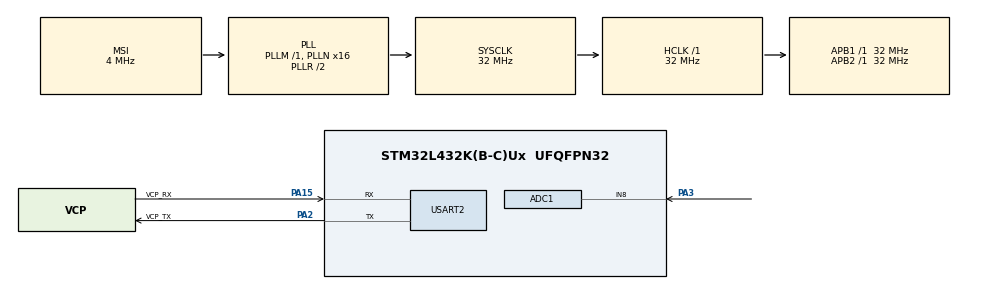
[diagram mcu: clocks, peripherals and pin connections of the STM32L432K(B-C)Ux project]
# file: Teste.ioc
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ADC1.Channel-0\#ChannelRegularConversion=ADC_CHANNEL_8
ADC1.ClockPrescaler=ADC_CLOCK_ASYNC_DIV1
ADC1.EnableInjectedConversion=DISABLE
ADC1.NbrOfConversionFlag=1
ADC1.OffsetNumber-0\#ChannelRegularConversion=ADC_OFFSET_NONE
ADC1.Overrun=ADC_OVR_DATA_PRESERVED
ADC1.Rank-0\#ChannelRegularConversion=1
ADC1.SamplingTime-0\#ChannelRegularConversion=ADC_SAMPLETIME_2CYCLES_5
ADC1.master=1
Mcu.Family=STM32L4
Mcu.Name=STM32L432K(B-C)Ux
Mcu.Package=UFQFPN32
NVIC.ADC1_IRQn=true\:0\:0\:false\:false\:true\:true\:true
NVIC.PriorityGroup=NVIC_PRIORITYGROUP_4
NVIC.TIM1_UP_TIM16_IRQn=true\:0\:0\:false\:false\:true\:true\:true
PA0.GPIO_Label=MCO [High speed clock in]
PA0.Mode=HSE-External-Clock-Source-for-LittleOrca
PA0.Signal=RCC_CK_IN
PA13\ (JTMS-SWDIO).GPIO_Label=SWDIO
PA13\ (JTMS-SWDIO).Mode=Trace_Asynchronous_SW
PA13\ (JTMS-SWDIO).Signal=SYS_JTMS-SWDIO
PA14\ (JTCK-SWCLK).GPIO_Label=SWCLK
PA14\ (JTCK-SWCLK).Mode=Trace_Asynchronous_SW
PA14\ (JTCK-SWCLK).Signal=SYS_JTCK-SWCLK
PA15\ (JTDI).GPIO_Label=VCP_RX
PA15\ (JTDI).Mode=Asynchronous
PA15\ (JTDI).Signal=USART2_RX
PA2.GPIO_Label=VCP_TX
PA2.Mode=Asynchronous
PA2.Signal=USART2_TX
PA3.Signal=ADCx_IN8
PB3\ (JTDO-TRACESWO).Mode=Trace_Asynchronous_SW
PB3\ (JTDO-TRACESWO).Signal=SYS_JTDO-SWO
PC14-OSC32_IN\ (PC14).Mode=LSE-External-Oscillator
PC14-OSC32_IN\ (PC14).Signal=RCC_OSC32_IN
PC15-OSC32_OUT\ (PC15).Mode=LSE-External-Oscillator
PC15-OSC32_OUT\ (PC15).Signal=RCC_OSC32_OUT
ProjectManager.HeapSize=0x200
ProjectManager.StackSize=0x400
ProjectManager.TargetToolchain=STM32CubeIDE
RCC.ADCFreq_Value=8000000
RCC.AHBFreq_Value=32000000
RCC.APB1Freq_Value=32000000
RCC.APB1TimFreq_Value=32000000
RCC.APB2Freq_Value=32000000
RCC.APB2TimFreq_Value=32000000
RCC.CortexFreq_Value=32000000
RCC.HCLKFreq_Value=32000000
RCC.HSE_VALUE=8000000
RCC.HSI16_VALUE=16000000
RCC.HSI48_VALUE=48000000
RCC.HSI_VALUE=16000000
RCC.MSI_VALUE=4000000
RCC.PLLMUL=RCC_PLLMUL_4
RCC.PLLN=16
RCC.PLLSAI1N=16
RCC.PLLSAI1R=RCC_PLLR_DIV8
RCC.SYSCLKFreq_VALUE=32000000
RCC.SYSCLKSource=RCC_SYSCLKSOURCE_PLLCLK
RCC.USBFreq_Value=32000000
RCC.VCOOutputFreq_Value=64000000
SH.ADCx_IN8.0=ADC1_IN8,IN8-Single-Ended
TIM16.Period=8000
USART2.VirtualMode-Asynchronous=VM_ASYNC
VP_TIM16_VS_ClockSourceINT.Mode=Enable_Timer
board=NUCLEO-L432KC

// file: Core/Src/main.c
/* USER CODE BEGIN Header */
/**
  ******************************************************************************
  * @file           : main.c
  * @brief          : Main program body
  ******************************************************************************
  * @attention
  *
  * <h2><center>&copy; Copyright (c) 2021 STMicroelectronics.
  * All rights reserved.</center></h2>
  *
  * This software component is licensed by ST under BSD 3-Clause license,
  * the "License"; You may not use this file except in compliance with the
  * License. You may obtain a copy of the License at:
  *                        opensource.org/licenses/BSD-3-Clause
  *
  ******************************************************************************
  */
/* USER CODE END Header */
#include "main.h"

ADC_HandleTypeDef hadc1;

TIM_HandleTypeDef htim16;

UART_HandleTypeDef huart2;

/* USER CODE BEGIN PV */
volatile uint32_t amostra;

/* USER CODE END PV */

void SystemClock_Config(void);
static void MX_GPIO_Init(void);
static void MX_USART2_UART_Init(void);
static void MX_ADC1_Init(void);
static void MX_TIM16_Init(void);

/* USER CODE BEGIN 0 */
void HAL_TIM_PeriodElapsedCallback(TIM_HandleTypeDef *htim)
{
	if( htim->Instance == htim16.Instance )
	{
		HAL_ADCEx_Calibration_Start(&hadc1, ADC_SINGLE_ENDED);
		HAL_ADC_Start(&hadc1);
		if( HAL_ADC_PollForConversion(&hadc1, 1) == HAL_TIMEOUT )
		{
		 // Sinalizar falha de timeout.
		}
		amostra = HAL_ADC_GetValue(&hadc1);
	}
}
/* USER CODE END 0 */

int main(void)
{

  /* MCU Configuration--------------------------------------------------------*/

  /* Reset of all peripherals, Initializes the Flash interface and the Systick. */
  HAL_Init();

  /* Configure the system clock */
  SystemClock_Config();

  /* Initialize all configured peripherals */
  MX_GPIO_Init();
  MX_USART2_UART_Init();
  MX_ADC1_Init();
  MX_TIM16_Init();
  /* USER CODE BEGIN 2 */
  HAL_TIM_Base_Start_IT(&htim16);
  /* USER CODE END 2 */

  /* Infinite loop */
  while (1)
  {

  }
}

void SystemClock_Config(void)
{
  RCC_OscInitTypeDef RCC_OscInitStruct = {0};
  RCC_ClkInitTypeDef RCC_ClkInitStruct = {0};

  /** Configure the main internal regulator output voltage
  */
  if (HAL_PWREx_ControlVoltageScaling(PWR_REGULATOR_VOLTAGE_SCALE1) != HAL_OK)
  {
    Error_Handler();
  }
  /** Configure LSE Drive Capability
  */
  HAL_PWR_EnableBkUpAccess();
  __HAL_RCC_LSEDRIVE_CONFIG(RCC_LSEDRIVE_LOW);
  /** Initializes the RCC Oscillators according to the specified parameters
  * in the RCC_OscInitTypeDef structure.
  */
  RCC_OscInitStruct.OscillatorType = RCC_OSCILLATORTYPE_LSE|RCC_OSCILLATORTYPE_MSI;
  RCC_OscInitStruct.LSEState = RCC_LSE_ON;
  RCC_OscInitStruct.MSIState = RCC_MSI_ON;
  RCC_OscInitStruct.MSICalibrationValue = 0;
  RCC_OscInitStruct.MSIClockRange = RCC_MSIRANGE_6;
  RCC_OscInitStruct.PLL.PLLState = RCC_PLL_ON;
  RCC_OscInitStruct.PLL.PLLSource = RCC_PLLSOURCE_MSI;
  RCC_OscInitStruct.PLL.PLLM = 1;
  RCC_OscInitStruct.PLL.PLLN = 16;
  RCC_OscInitStruct.PLL.PLLP = RCC_PLLP_DIV7;
  RCC_OscInitStruct.PLL.PLLQ = RCC_PLLQ_DIV2;
  RCC_OscInitStruct.PLL.PLLR = RCC_PLLR_DIV2;
  if (HAL_RCC_OscConfig(&RCC_OscInitStruct) != HAL_OK)
  {
    Error_Handler();
  }
  /** Initializes the CPU, AHB and APB buses clocks
  */
  RCC_ClkInitStruct.ClockType = RCC_CLOCKTYPE_HCLK|RCC_CLOCKTYPE_SYSCLK
                              |RCC_CLOCKTYPE_PCLK1|RCC_CLOCKTYPE_PCLK2;
  RCC_ClkInitStruct.SYSCLKSource = RCC_SYSCLKSOURCE_PLLCLK;
  RCC_ClkInitStruct.AHBCLKDivider = RCC_SYSCLK_DIV1;
  RCC_ClkInitStruct.APB1CLKDivider = RCC_HCLK_DIV1;
  RCC_ClkInitStruct.APB2CLKDivider = RCC_HCLK_DIV1;

  if (HAL_RCC_ClockConfig(&RCC_ClkInitStruct, FLASH_LATENCY_1) != HAL_OK)
  {
    Error_Handler();
  }
  /** Enable MSI Auto calibration
  */
  HAL_RCCEx_EnableMSIPLLMode();
}

static void MX_ADC1_Init(void)
{

  ADC_ChannelConfTypeDef sConfig = {0};

  /** Common config
  */
  hadc1.Instance = ADC1;
  hadc1.Init.ClockPrescaler = ADC_CLOCK_ASYNC_DIV1;
  hadc1.Init.Resolution = ADC_RESOLUTION_12B;
  hadc1.Init.DataAlign = ADC_DATAALIGN_RIGHT;
  hadc1.Init.ScanConvMode = ADC_SCAN_DISABLE;
  hadc1.Init.EOCSelection = ADC_EOC_SINGLE_CONV;
  hadc1.Init.LowPowerAutoWait = DISABLE;
  hadc1.Init.ContinuousConvMode = DISABLE;
  hadc1.Init.NbrOfConversion = 1;
  hadc1.Init.DiscontinuousConvMode = DISABLE;
  hadc1.Init.ExternalTrigConv = ADC_SOFTWARE_START;
  hadc1.Init.ExternalTrigConvEdge = ADC_EXTERNALTRIGCONVEDGE_NONE;
  hadc1.Init.DMAContinuousRequests = DISABLE;
  hadc1.Init.Overrun = ADC_OVR_DATA_PRESERVED;
  hadc1.Init.OversamplingMode = DISABLE;
  if (HAL_ADC_Init(&hadc1) != HAL_OK)
  {
    Error_Handler();
  }
  /** Configure Regular Channel
  */
  sConfig.Channel = ADC_CHANNEL_8;
  sConfig.Rank = ADC_REGULAR_RANK_1;
  sConfig.SamplingTime = ADC_SAMPLETIME_2CYCLES_5;
  sConfig.SingleDiff = ADC_SINGLE_ENDED;
  sConfig.OffsetNumber = ADC_OFFSET_NONE;
  sConfig.Offset = 0;
  if (HAL_ADC_ConfigChannel(&hadc1, &sConfig) != HAL_OK)
  {
    Error_Handler();
  }

}

static void MX_TIM16_Init(void)
{

  htim16.Instance = TIM16;
  htim16.Init.Prescaler = 0;
  htim16.Init.CounterMode = TIM_COUNTERMODE_UP;
  htim16.Init.Period = 8000;
  htim16.Init.ClockDivision = TIM_CLOCKDIVISION_DIV1;
  htim16.Init.RepetitionCounter = 0;
  htim16.Init.AutoReloadPreload = TIM_AUTORELOAD_PRELOAD_DISABLE;
  if (HAL_TIM_Base_Init(&htim16) != HAL_OK)
  {
    Error_Handler();
  }

}

static void MX_USART2_UART_Init(void)
{

  huart2.Instance = USART2;
  huart2.Init.BaudRate = 115200;
  huart2.Init.WordLength = UART_WORDLENGTH_8B;
  huart2.Init.StopBits = UART_STOPBITS_1;
  huart2.Init.Parity = UART_PARITY_NONE;
  huart2.Init.Mode = UART_MODE_TX_RX;
  huart2.Init.HwFlowCtl = UART_HWCONTROL_NONE;
  huart2.Init.OverSampling = UART_OVERSAMPLING_16;
  huart2.Init.OneBitSampling = UART_ONE_BIT_SAMPLE_DISABLE;
  huart2.AdvancedInit.AdvFeatureInit = UART_ADVFEATURE_NO_INIT;
  if (HAL_UART_Init(&huart2) != HAL_OK)
  {
    Error_Handler();
  }

}

static void MX_GPIO_Init(void)
{
  GPIO_InitTypeDef GPIO_InitStruct = {0};

  /* GPIO Ports Clock Enable */
  __HAL_RCC_GPIOC_CLK_ENABLE();
  __HAL_RCC_GPIOA_CLK_ENABLE();
  __HAL_RCC_GPIOB_CLK_ENABLE();
  __HAL_RCC_GPIOH_CLK_ENABLE();

  /*Configure GPIO pins : PA1 PA4 PA5 PA6
                           PA7 PA8 PA9 PA10
                           PA11 PA12 */
  GPIO_InitStruct.Pin = GPIO_PIN_1|GPIO_PIN_4|GPIO_PIN_5|GPIO_PIN_6
                          |GPIO_PIN_7|GPIO_PIN_8|GPIO_PIN_9|GPIO_PIN_10
                          |GPIO_PIN_11|GPIO_PIN_12;
  GPIO_InitStruct.Mode = GPIO_MODE_ANALOG;
  GPIO_InitStruct.Pull = GPIO_NOPULL;
  HAL_GPIO_Init(GPIOA, &GPIO_InitStruct);

  /*Configure GPIO pins : PB0 PB1 PB4 PB5
                           PB6 PB7 */
  GPIO_InitStruct.Pin = GPIO_PIN_0|GPIO_PIN_1|GPIO_PIN_4|GPIO_PIN_5
                          |GPIO_PIN_6|GPIO_PIN_7;
  GPIO_InitStruct.Mode = GPIO_MODE_ANALOG;
  GPIO_InitStruct.Pull = GPIO_NOPULL;
  HAL_GPIO_Init(GPIOB, &GPIO_InitStruct);

  /*Configure GPIO pin : PH3 */
  GPIO_InitStruct.Pin = GPIO_PIN_3;
  GPIO_InitStruct.Mode = GPIO_MODE_ANALOG;
  GPIO_InitStruct.Pull = GPIO_NOPULL;
  HAL_GPIO_Init(GPIOH, &GPIO_InitStruct);

}

void Error_Handler(void)
{
  __disable_irq();
  while (1)
  {
  }
}

/************************ (C) COPYRIGHT STMicroelectronics *****END OF FILE****/
